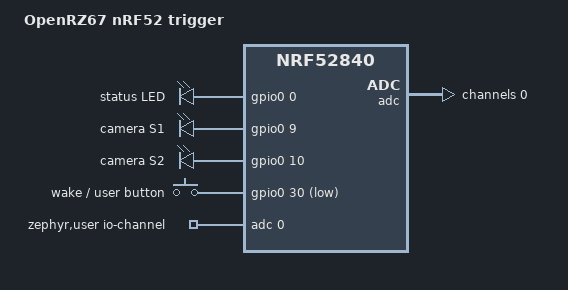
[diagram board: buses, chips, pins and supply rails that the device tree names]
/dts-v1/;
#include <nordic/nrf52840_qiaa.dtsi>
#include <zephyr/dt-bindings/input/input-event-codes.h>
#include <zephyr/dt-bindings/adc/adc.h>
#include <zephyr/dt-bindings/adc/nrf-adc.h>

/ {
	model = "OpenRZ67 nRF52 trigger";
	compatible = "openrz67,openrz67-nrf";

	chosen {
		zephyr,sram = &sram0;
		zephyr,flash = &flash0;
		zephyr,code-partition = &slot0_partition;
	};

	/* E73-2G4M08S1C pads -> nRF52840 GPIO, see ../../../kicad/README.md */
	outputs {
		compatible = "gpio-leds";
		status_led: led_0 {
			gpios = <&gpio0 0 GPIO_ACTIVE_HIGH>;	/* D1 through R3, pad 11 (XL1) */
			label = "status LED";
		};
		s1_drv: s1 {
			gpios = <&gpio0 9 GPIO_ACTIVE_HIGH>;	/* U2 PhotoMOS LED through R1, pad 41 (NFC1) */
			label = "camera S1";
		};
		s2_drv: s2 {
			gpios = <&gpio0 10 GPIO_ACTIVE_HIGH>;	/* U3 PhotoMOS LED through R2, pad 43 (NFC2) */
			label = "camera S2";
		};
	};

	buttons {
		compatible = "gpio-keys";
		user_button: button_0 {
			gpios = <&gpio0 30 (GPIO_PULL_UP | GPIO_ACTIVE_LOW)>;	/* SW1 to GND, pad 10 */
			label = "wake / user button";
			zephyr,code = <INPUT_KEY_0>;
		};
	};

	zephyr,user {
		io-channels = <&adc 0>;	/* VDD, i.e. the cell voltage */
	};

	aliases {
		led0 = &status_led;
		sw0 = &user_button;
	};
};

&adc {
	status = "okay";
	#address-cells = <1>;
	#size-cells = <0>;
	channel@0 {
		reg = <0>;
		zephyr,gain = "ADC_GAIN_1_6";
		zephyr,reference = "ADC_REF_INTERNAL";
		zephyr,acquisition-time = <ADC_ACQ_TIME(ADC_ACQ_TIME_MICROSECONDS, 40)>;
		zephyr,input-positive = <NRF_SAADC_VDD>;
		zephyr,resolution = <12>;
		zephyr,oversampling = <4>;
	};
};

&gpio0 {
	status = "okay";
};

&gpio1 {
	status = "okay";
};

&gpiote {
	status = "okay";
};

/* P0.09 / P0.10 drive the PhotoMOS LEDs, not NFC */
&uicr {
	nfct-pins-as-gpios;
};

&flash0 {
	partitions {
		compatible = "fixed-partitions";
		#address-cells = <1>;
		#size-cells = <1>;
		boot_partition: partition@0 {
			label = "mcuboot";
			reg = <0x0 0xc000>;
		};
		slot0_partition: partition@c000 {
			label = "image-0";
			reg = <0xc000 0x72000>;
		};
		slot1_partition: partition@7e000 {
			label = "image-1";
			reg = <0x7e000 0x72000>;
		};
		storage_partition: partition@f0000 {
			label = "storage";
			reg = <0xf0000 0x10000>;
		};
	};
};
